# AT90USB1287 device description
Architecture: AVR8; Family: megaAVR
Registers are 8-bit, access not given, no defined reset value unless marked. A register's access mark holds for its fields unless they carry their own. Offsets are from the block's base; [hi:lo] are bit positions.

## USB_HOST — USB Host Registers
Instances: USB_HOST 0x00
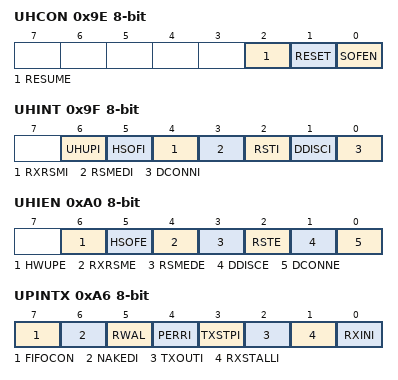
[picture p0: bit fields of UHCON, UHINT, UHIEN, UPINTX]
0x9E UHCON
  [2] RESUME, [1] RESET, [0] SOFEN
0x9F UHINT
  [6] UHUPI, [5] HSOFI, [4] RXRSMI, [3] RSMEDI, [2] RSTI, [1] DDISCI, [0] DCONNI
0xA0 UHIEN
  [6] HWUPE, [5] HSOFE, [4] RXRSME, [3] RSMEDE, [2] RSTE, [1] DDISCE, [0] DCONNE
0xA1 UHADDR bits used 6:0
0xA2 UHFNUM 16-bit bits used 10:0
0xA4 UHFLEN
0xA5 UPINRQX
0xA6 UPINTX
  [7] FIFOCON, [6] NAKEDI, [5] RWAL, [4] PERRI, [3] TXSTPI, [2] TXOUTI, [1] RXSTALLI, [0] RXINI
0xA7 UPNUM bits used 2:0
0xA8 UPRST
  [6:0] PRST
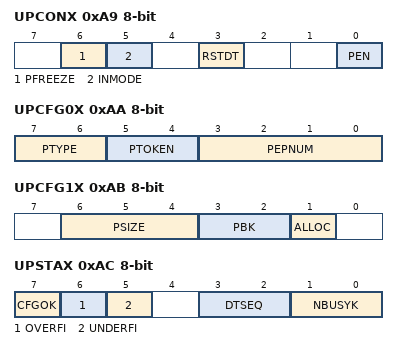
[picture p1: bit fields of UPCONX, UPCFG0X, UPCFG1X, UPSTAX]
0xA9 UPCONX
  [6] PFREEZE, [5] INMODE, [3] RSTDT, [0] PEN
0xAA UPCFG0X
  [7:6] PTYPE, [5:4] PTOKEN, [3:0] PEPNUM
0xAB UPCFG1X
  [6:4] PSIZE, [3:2] PBK, [1] ALLOC
0xAC UPSTAX
  [7] CFGOK, [6] OVERFI, [5] UNDERFI, [3:2] DTSEQ, [1:0] NBUSYK
0xAD UPCFG2X
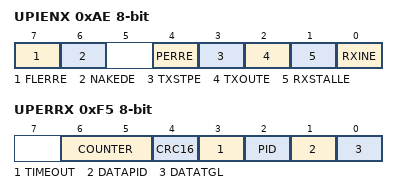
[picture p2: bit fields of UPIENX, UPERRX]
0xAE UPIENX
  [7] FLERRE, [6] NAKEDE, [4] PERRE, [3] TXSTPE, [2] TXOUTE, [1] RXSTALLE, [0] RXINE
0xAF UPDATX
0xF5 UPERRX
  [6:5] COUNTER, [4] CRC16, [3] TIMEOUT, [2] PID, [1] DATAPID, [0] DATATGL
0xF6 UPBCLX
0xF7 UPBCHX bits used 2:0
0xF8 UPINT bits used 6:0

## BOOT_LOAD — Bootloader
Instances: BOOT_LOAD 0x00
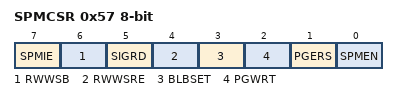
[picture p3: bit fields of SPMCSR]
0x57 SPMCSR — Store Program Memory Control Register
  [7] SPMIE — SPM Interrupt Enable
  [6] RWWSB — Read While Write Section Busy
  [5] SIGRD — Signature Row Read
  [4] RWWSRE — Read While Write section read enable
  [3] BLBSET — Boot Lock Bit Set
  [2] PGWRT — Page Write
  [1] PGERS — Page Erase
  [0] SPMEN — Store Program Memory Enable

## EEPROM
Instances: EEPROM 0x00
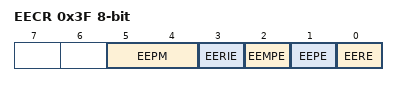
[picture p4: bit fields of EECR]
0x3F EECR — EEPROM Control Register
  [5:4] EEPM — EEPROM Programming Mode Bits
    0=Erase and Write in one operation; 1=Erase Only; 2=Write Only
  [3] EERIE — EEPROM Ready Interrupt Enable
  [2] EEMPE — EEPROM Master Write Enable
  [1] EEPE — EEPROM Write Enable
  [0] EERE — EEPROM Read Enable
0x40 EEDR — EEPROM Data Register
0x41 EEAR 16-bit bits used 11:0 — EEPROM Address Register Low Bytes

## TC0 (TC8 module) — Timer/Counter, 8-bit
Instances: TC0 0x00
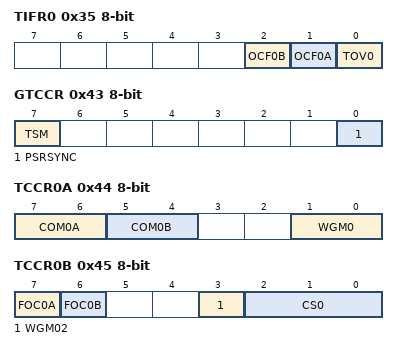
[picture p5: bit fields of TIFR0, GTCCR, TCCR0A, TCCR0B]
0x35 TIFR0 — Timer/Counter0 Interrupt Flag register
  [2] OCF0B — Timer/Counter0 Output Compare Flag 0B
  [1] OCF0A — Timer/Counter0 Output Compare Flag 0A
  [0] TOV0 — Timer/Counter0 Overflow Flag
0x43 GTCCR — General Timer/Counter Control Register
  [7] TSM — Timer/Counter Synchronization Mode
  [0] PSRSYNC — Prescaler Reset Timer/Counter1 and Timer/Counter0
0x44 TCCR0A — Timer/Counter Control Register A
  [7:6] COM0A — Compare Output Mode, Phase Correct PWM Mode
  [5:4] COM0B — Compare Output Mode, Fast PWm
  [1:0] WGM0 — Waveform Generation Mode
0x45 TCCR0B — Timer/Counter Control Register B
  [7] FOC0A — Force Output Compare A
  [6] FOC0B — Force Output Compare B
  [3] WGM02
  [2:0] CS0 — Clock Select
    0=No Clock Source (Stopped); 1=Running, No Prescaling; 2=Running, CLK/8; 3=Running, CLK/64; 4=Running, CLK/256; 5=Running, CLK/1024; 6=Running, ExtClk Tx Falling Edge; 7=Running, ExtClk Tx Rising Edge
0x46 TCNT0 — Timer/Counter0
0x47 OCR0A — Timer/Counter0 Output Compare Register
0x48 OCR0B — Timer/Counter0 Output Compare Register
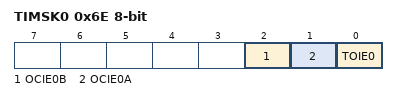
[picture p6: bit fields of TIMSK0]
0x6E TIMSK0 — Timer/Counter0 Interrupt Mask Register
  [2] OCIE0B — Timer/Counter0 Output Compare Match B Interrupt Enable
  [1] OCIE0A — Timer/Counter0 Output Compare Match A Interrupt Enable
  [0] TOIE0 — Timer/Counter0 Overflow Interrupt Enable

## TC2 (TC8_ASYNC module) — Timer/Counter, 8-bit Async
Instances: TC2 0x00
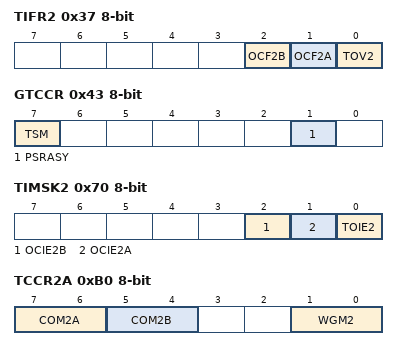
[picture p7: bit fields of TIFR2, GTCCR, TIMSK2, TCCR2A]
0x37 TIFR2 — Timer/Counter Interrupt Flag Register
  [2] OCF2B — Output Compare Flag 2B
  [1] OCF2A — Output Compare Flag 2A
  [0] TOV2 — Timer/Counter2 Overflow Flag
0x43 GTCCR — General Timer Counter Control register
  [7] TSM — Timer/Counter Synchronization Mode
  [1] PSRASY — Prescaler Reset Timer/Counter2
0x70 TIMSK2 — Timer/Counter Interrupt Mask register
  [2] OCIE2B — Timer/Counter2 Output Compare Match B Interrupt Enable
  [1] OCIE2A — Timer/Counter2 Output Compare Match A Interrupt Enable
  [0] TOIE2 — Timer/Counter2 Overflow Interrupt Enable
0xB0 TCCR2A — Timer/Counter2 Control Register A
  [7:6] COM2A — Compare Output Mode bits
  [5:4] COM2B — Compare Output Mode bits
  [1:0] WGM2 — Waveform Genration Mode
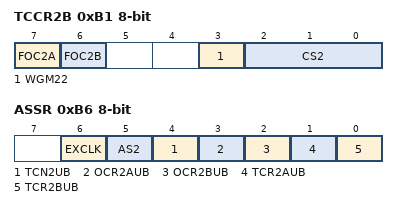
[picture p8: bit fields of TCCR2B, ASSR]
0xB1 TCCR2B — Timer/Counter2 Control Register B
  [7] FOC2A — Force Output Compare A
  [6] FOC2B — Force Output Compare B
  [3] WGM22 — Waveform Generation Mode
  [2:0] CS2 — Clock Select bits
    0=No Clock Source (Stopped); 1=Running, No Prescaling; 2=Running, CLK/8; 3=Running, CLK/32; 4=Running, CLK/64; 5=Running, CLK/128; 6=Running, CLK/256; 7=Running, CLK/1024
0xB2 TCNT2 — Timer/Counter2
0xB3 OCR2A — Timer/Counter2 Output Compare Register A
0xB4 OCR2B — Timer/Counter2 Output Compare Register B
0xB6 ASSR — Asynchronous Status Register
  [6] EXCLK — Enable External Clock Input
  [5] AS2 — Asynchronous Timer/Counter2
  [4] TCN2UB — Timer/Counter2 Update Busy
  [3] OCR2AUB — Output Compare Register2 Update Busy
  [2] OCR2BUB — Output Compare Register 2 Update Busy
  [1] TCR2AUB — Timer/Counter Control Register2 Update Busy
  [0] TCR2BUB — Timer/Counter Control Register2 Update Busy
